# TC37X register map
File version: 1.0.0
CPU: CM4 r0p1, little endian, MPU, FPU, VTOR, 3 interrupt priority bits
Registers are 16-bit, read-write, reset 0x0 unless marked. A register's access mark holds for its fields unless they carry their own. Offsets are from the block's base; [hi:lo] are bit positions; {n}, {i} and the like mark numbered series.

## ASCLIN0 — ce_asclin
Base 0xF0000600
Same registers: ASCLIN{n} {0xF0000600+0x100*n} (n=1..9), ASCLIN10 0xF02C0A00, ASCLIN11 0xF02C0B00
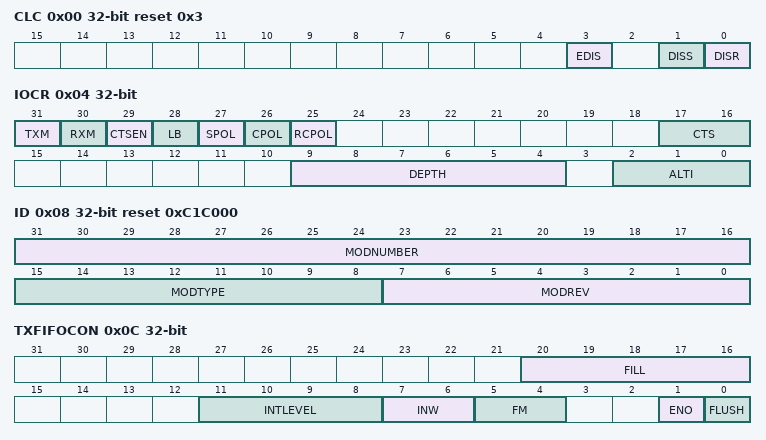
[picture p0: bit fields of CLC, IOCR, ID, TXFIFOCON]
0x00 CLC 32-bit reset 0x3 — Clock Control Register
  [3] EDIS — Sleep Mode Enable Control - EDIS
  [1] DISS ro — Module Disable Status Bit - DISS
  [0] DISR — Module Disable Request Bit - DISR
0x04 IOCR 32-bit (reset mask 0xFFFFFFF) — Input and Output Control Register
  [31] TXM ro — Transmit Monitor - TXM
  [30] RXM ro — Receive Monitor - RXM
  [29] CTSEN — Input Signal CTS Enable - CTSEN
  [28] LB — Loop Back Mode - LB
  [27] SPOL — Slave Polarity in Synchronous Mode - SPOL
  [26] CPOL — Clock Polarity in Synchronous Mode - CPOL
  [25] RCPOL — RTS CTS Polarity - RCPOL
  [17:16] CTS — CTS Select - CTS
  [9:4] DEPTH — Digital Glitch Filter Depth - DEPTH
  [2:0] ALTI — Alternate Input Select - ALTI
0x08 ID 32-bit ro reset 0xC1C000 (reset mask 0xFFFFFF00) — Module Identification Register
  [31:16] MODNUMBER — Module Number Value - MODNUMBER
  [15:8] MODTYPE — Module Type - MODTYPE
  [7:0] MODREV — Module Revision Number - MODREV
0x0C TXFIFOCON 32-bit — TX FIFO Configuration Register
  [20:16] FILL ro — FIFO Filling Level - FILL
  [11:8] INTLEVEL — FIFO Interrupt Level - INTLEVEL
  [7:6] INW — Transmit FIFO Inlet Width - INW
  [5:4] FM — TXFIFO Mode - FM
  [1] ENO — Transmit FIFO Outlet Enable - ENO
  [0] FLUSH wo — Flush the transmit FIFO - FLUSH
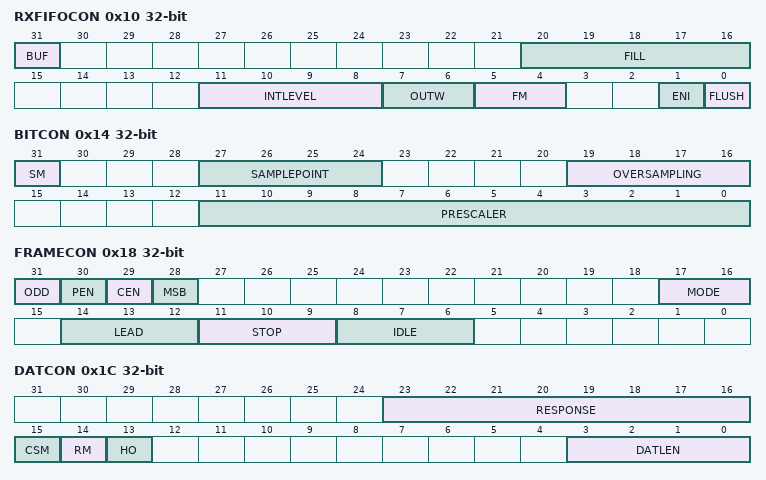
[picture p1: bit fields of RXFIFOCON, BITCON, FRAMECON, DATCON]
0x10 RXFIFOCON 32-bit — RX FIFO Configuration Register
  [31] BUF — Receive Buffer Mode - BUF
  [20:16] FILL ro — FIFO Filling Level - FILL
  [11:8] INTLEVEL — FIFO Interrupt Level - INTLEVEL
  [7:6] OUTW — Receive FIFO Outlet Width - OUTW
  [5:4] FM — RXFIFO Mode - FM
  [1] ENI — Receive FIFO Inlet Enable - ENI
  [0] FLUSH wo — Flush the receive FIFO - FLUSH
0x14 BITCON 32-bit — Bit Configuration Register
  [31] SM — Sample Mode - SM
  [27:24] SAMPLEPOINT — Sample Point Position - SAMPLEPOINT
  [19:16] OVERSAMPLING — Oversampling Factor - OVERSAMPLING
  [11:0] PRESCALER — Prescaling of the Fractional Divider - PRESCALER
0x18 FRAMECON 32-bit — Frame Control Register
  [31] ODD — Parity Type - ODD
  [30] PEN — Parity Enable - PEN
  [29] CEN — Collision Detection Enable - CEN
  [28] MSB — Shift Direction - MSB
  [17:16] MODE — Mode Selection - MODE
  [14:12] LEAD — Duration of the Leading Delay - LEAD
  [11:9] STOP — Number of Stop Bits - STOP
  [8:6] IDLE — Duration of the IDLE delay - IDLE
0x1C DATCON 32-bit — Data Configuration Register
  [23:16] RESPONSE — Response Timeout Threshold Value - RESPONSE
  [15] CSM — Checksum Mode - CSM
  [14] RM — Response Mode - RM
  [13] HO — Header Only - HO
  [3:0] DATLEN — Data Length - DATLEN
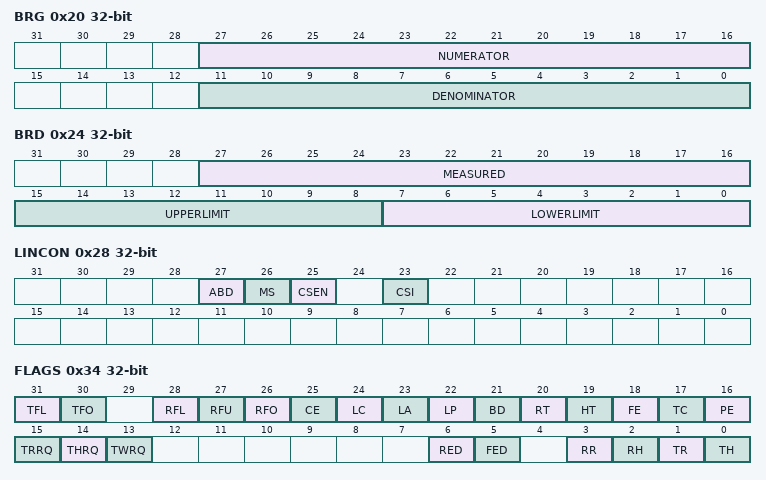
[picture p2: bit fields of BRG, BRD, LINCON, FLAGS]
0x20 BRG 32-bit — Baud Rate Generation Register
  [27:16] NUMERATOR — Numerator - NUMERATOR
  [11:0] DENOMINATOR — Denominator - DENOMINATOR
0x24 BRD 32-bit — Baud Rate Detection Register
  [27:16] MEASURED ro — Measured Value of 8-bits from Sync Field - MEASURED
  [15:8] UPPERLIMIT — Upper Limit - UPPERLIMIT
  [7:0] LOWERLIMIT — Lower Limit - LOWERLIMIT
0x28 LINCON 32-bit — LIN Control Register
  [27] ABD — Autobaud Detection - ABD
  [26] MS — Master Slave Mode - MS
  [25] CSEN — Hardware Checksum Enable - CSEN
  [23] CSI — Checksum Injection - CSI
0x2C LINBTIMER 32-bit — LIN Break Timer Register
  [5:0] BREAK — Break Pulse Generation and Detection - BREAK
0x30 LINHTIMER 32-bit — LIN Header Timer Register
  [7:0] HEADER — Header Timeout Threshold Value - HEADER
0x34 FLAGS 32-bit ro
  [31] TFL — Transmit FIFO Level Flag - TFL
  [30] TFO — Transmit FIFO Overflow Flag - TFO
  [28] RFL — Receive FIFO Level Flag - RFL
  [27] RFU — Receive FIFO Underflow Flag - RFU
  [26] RFO — Receive FIFO Overflow Flag - RFO
  [25] CE — Collision Detection Error Flag - CE
  [24] LC — LIN Checksum Error Flag - LC
  [23] LA — LIN Autobaud Detection Error Flag - LA
  [22] LP — LIN Parity Error Flag - LP
  [21] BD — Break Detected Flag - BD
  [20] RT — Response Timeout Flag - RT
  [19] HT — Header Timeout Flag - HT
  [18] FE — Framing Error Flag - FE
  [17] TC — Transmission Completed Flag - TC
  [16] PE — Parity Error Flag - PE
  [15] TRRQ — Transmit Response Request Flag - TRRQ
  [14] THRQ — Transmit Header Request Flag - THRQ
  [13] TWRQ — Transmit Wake Request Flag - TWRQ
  [6] RED — Rising Edge from Level 0 to Level 1 Detected - RED
  [5] FED — Falling Edge from Level 1 to Level 0 Detected - FED
  [3] RR — Receive Response End Flag - RR
  [2] RH — Receive Header End Flag - RH
  [1] TR — Transmit Response End Flag - TR
  [0] TH — Transmit Header End Flag - TH
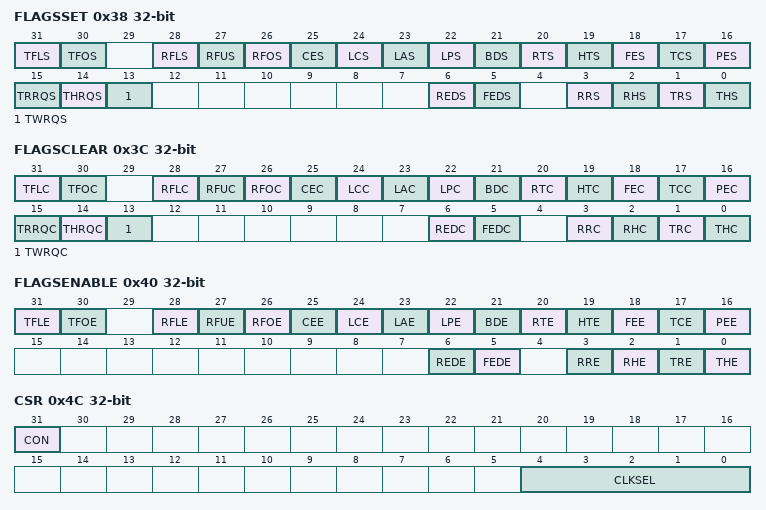
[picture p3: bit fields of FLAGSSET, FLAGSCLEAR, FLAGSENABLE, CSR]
0x38 FLAGSSET 32-bit
  [31] TFLS wo — Flag Set Bit - TFLS
  [30] TFOS wo — Flag Set Bit - TFOS
  [28] RFLS wo — Flag Set Bit - RFLS
  [27] RFUS wo — Flag Set Bit - RFUS
  [26] RFOS wo — Flag Set Bit - RFOS
  [25] CES wo — Flag Set Bit - CES
  [24] LCS wo — Flag Set Bit - LCS
  [23] LAS wo — Flag Set Bit - LAS
  [22] LPS wo — Flag Set Bit - LPS
  [21] BDS wo — Flag Set Bit - BDS
  [20] RTS wo — Flag Set Bit - RTS
  [19] HTS wo — Flag Set Bit - HTS
  [18] FES wo — Flag Set Bit - FES
  [17] TCS wo — Flag Set Bit - TCS
  [16] PES wo — Flag Set Bit - PES
  [15] TRRQS wo — Flag Set Bit - TRRQS
  [14] THRQS wo — Flag Set Bit - THRQS
  [13] TWRQS wo — Flag Set Bit - TWRQS
  [6] REDS wo — Flag Set Bit - REDS
  [5] FEDS wo — Flag Set Bit - FEDS
  [3] RRS wo — Flag Set Bit - RRS
  [2] RHS wo — Flag Set Bit - RHS
  [1] TRS wo — Flag Set Bit - TRS
  [0] THS wo — Flag Set Bit - THS
0x3C FLAGSCLEAR 32-bit
  [31] TFLC wo — Flag Clear Bit - TFLC
  [30] TFOC wo — Flag Clear Bit - TFOC
  [28] RFLC wo — Flag Clear Bit - RFLC
  [27] RFUC wo — Flag Clear Bit - RFUC
  [26] RFOC wo — Flag Clear Bit - RFOC
  [25] CEC wo — Flag Clear Bit - CEC
  [24] LCC wo — Flag Clear Bit - LCC
  [23] LAC wo — Flag Clear Bit - LAC
  [22] LPC wo — Flag Clear Bit - LPC
  [21] BDC wo — Flag Clear Bit - BDC
  [20] RTC wo — Flag Clear Bit - RTC
  [19] HTC wo — Flag Clear Bit - HTC
  [18] FEC wo — Flag Clear Bit - FEC
  [17] TCC wo — Flag Clear Bit - TCC
  [16] PEC wo — Flag Clear Bit - PEC
  [15] TRRQC wo — Flag Clear Bit - TRRQC
  [14] THRQC wo — Flag Clear Bit - THRQC
  [13] TWRQC wo — Flag Clear Bit - TWRQC
  [6] REDC wo — Flag Clear Bit - REDC
  [5] FEDC wo — Flag Clear Bit - FEDC
  [3] RRC wo — Flag Clear Bit - RRC
  [2] RHC wo — Flag Clear Bit - RHC
  [1] TRC wo — Flag Clear Bit - TRC
  [0] THC wo — Flag Clear Bit - THC
0x40 FLAGSENABLE 32-bit
  [31] TFLE — Flag Enable Bit - TFLE
  [30] TFOE — Flag Enable Bit - TFOE
  [28] RFLE — Flag Enable Bit - RFLE
  [27] RFUE — Flag Enable Bit - RFUE
  [26] RFOE — Flag Enable Bit - RFOE
  [25] CEE — Flag Enable Bit - CEE
  [24] LCE — Flag Enable Bit - LCE
  [23] LAE — Flag Enable Bit - LAE
  [22] LPE — Flag Enable Bit - LPE
  [21] BDE — Flag Enable Bit - BDE
  [20] RTE — Flag Enable Bit - RTE
  [19] HTE — Flag Enable Bit - HTE
  [18] FEE — Flag Enable Bit - FEE
  [17] TCE — Flag Enable Bit - TCE
  [16] PEE — Flag Enable Bit - PEE
  [6] REDE — Flag Enable Bit - REDE
  [5] FEDE — Flag Enable Bit - FEDE
  [3] RRE — Flag Enable Bit - RRE
  [2] RHE — Flag Enable Bit - RHE
  [1] TRE — Flag Enable Bit - TRE
  [0] THE — Flag Enable Bit - THE
0x44 TXDATA 32-bit wo — Transmit Data Register
  [31:0] DATA — Data - DATA
0x48 RXDATA 32-bit ro — Receive Data Register
  [31:0] DATA — Data - DATA
0x4C CSR 32-bit — Clock Selection Register
  [31] CON ro — Clock On Flag - CON
  [4:0] CLKSEL — Baud Rate Logic Clock Select - CLKSEL
0x50 RXDATAD 32-bit ro — Receive Data Debug Register
  [31:0] DATA — Data - DATA
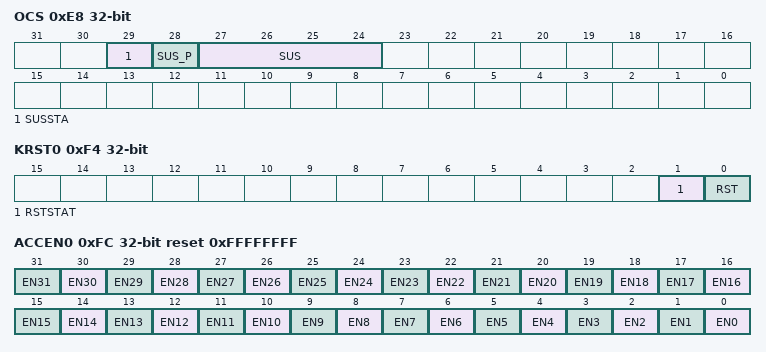
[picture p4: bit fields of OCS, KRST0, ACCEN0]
0xE8 OCS 32-bit — OCDS Control and Status
  [29] SUSSTA ro — Suspend State - SUSSTA
  [28] SUS_P wo — SUS Write Protection - SUS_P
  [27:24] SUS — OCDS Suspend Control - SUS
0xEC KRSTCLR 32-bit — Kernel Reset Status Clear Register
  [0] CLR wo — Kernel Reset Status Clear - CLR
0xF0 KRST1 32-bit — Kernel Reset Register 1
  [0] RST — Kernel Reset - RST
0xF4 KRST0 32-bit — Kernel Reset Register 0
  [1] RSTSTAT ro — Kernel Reset Status - RSTSTAT
  [0] RST — Kernel Reset - RST
0xF8 ACCEN1 32-bit ro — Access Enable Register 1
0xFC ACCEN0 32-bit reset 0xFFFFFFFF — Access Enable Register 0
  [n] EN{n} (n=0..31) — Access Enable for Master TAG ID {n} - EN{n}
